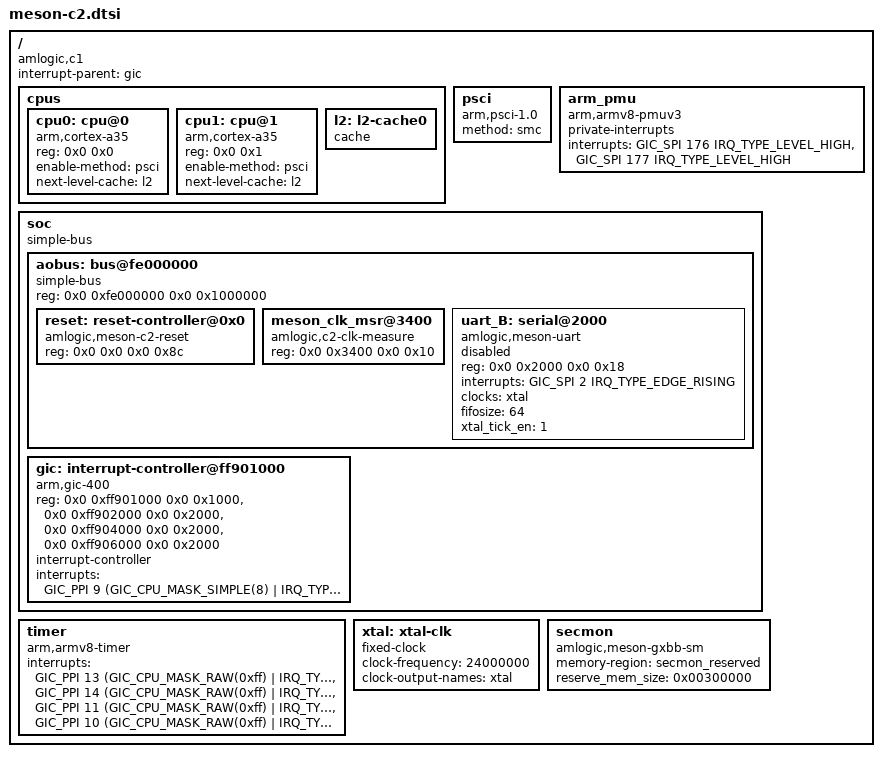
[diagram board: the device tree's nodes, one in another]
// SPDX-License-Identifier: (GPL-2.0+ OR MIT)
/*
 * Copyright (c) 2019 Amlogic, Inc. All rights reserved.
 */

#include <dt-bindings/interrupt-controller/irq.h>
#include <dt-bindings/interrupt-controller/arm-gic.h>

/ {
	compatible = "amlogic,c1";

	interrupt-parent = <&gic>;
	#address-cells = <2>;
	#size-cells = <2>;

	cpus {
		#address-cells = <2>;
		#size-cells = <0>;

		cpu0: cpu@0 {
			device_type = "cpu";
			compatible = "arm,cortex-a35";
			reg = <0x0 0x0>;
			enable-method = "psci";
			next-level-cache = <&l2>;
		};

		cpu1: cpu@1 {
			device_type = "cpu";
			compatible = "arm,cortex-a35";
			reg = <0x0 0x1>;
			enable-method = "psci";
			next-level-cache = <&l2>;
		};

		l2: l2-cache0 {
			compatible = "cache";
		};
	};

	psci {
		compatible = "arm,psci-1.0";
		method = "smc";
	};

	arm_pmu {
		compatible = "arm,armv8-pmuv3";
		/* clusterb-enabled; */
		private-interrupts;
		interrupts = <GIC_SPI 176 IRQ_TYPE_LEVEL_HIGH>,
			     <GIC_SPI 177 IRQ_TYPE_LEVEL_HIGH>;
	};

	soc {
		compatible = "simple-bus";
		#address-cells = <2>;
		#size-cells = <2>;
		ranges;

		aobus: bus@fe000000 {
			compatible = "simple-bus";
			reg = <0x0 0xfe000000 0x0 0x1000000>;
			#address-cells = <2>;
			#size-cells = <2>;
			ranges = <0x0 0x0 0x0 0xfe000000 0x0 0x1000000>;

			reset: reset-controller@0x0 {
				compatible = "amlogic,meson-c2-reset";
				reg = <0x0 0x0 0x0 0x8c>;
				#reset-cells = <1>;
			};

			meson_clk_msr@3400 {
				compatible = "amlogic,c2-clk-measure";
				reg = <0x0 0x3400 0x0 0x10>;
			};

			uart_B: serial@2000 {
				compatible = "amlogic,meson-uart";
				reg = <0x0 0x2000 0x0 0x18>;
				interrupts = <GIC_SPI 2 IRQ_TYPE_EDGE_RISING>;
				status = "disabled";
				clocks = <&xtal>;
				clock-names = "clk_uart";
				fifosize = < 64 >;
				xtal_tick_en = <1>;
				//pinctrl-names = "default";
				//pinctrl-0 = <&b_uart_enable_pins1>;
			};

		};

		gic: interrupt-controller@ff901000 {
			compatible = "arm,gic-400";
			reg = <0x0 0xff901000 0x0 0x1000>,
			      <0x0 0xff902000 0x0 0x2000>,
			      <0x0 0xff904000 0x0 0x2000>,
			      <0x0 0xff906000 0x0 0x2000>;
			interrupt-controller;
			interrupts = <GIC_PPI 9
				(GIC_CPU_MASK_SIMPLE(8) | IRQ_TYPE_LEVEL_HIGH)>;
			#interrupt-cells = <3>;
			#address-cells = <0>;
		};
	};

	timer {
		compatible = "arm,armv8-timer";
		interrupts = <GIC_PPI 13
			(GIC_CPU_MASK_RAW(0xff) | IRQ_TYPE_LEVEL_LOW)>,
			     <GIC_PPI 14
			(GIC_CPU_MASK_RAW(0xff) | IRQ_TYPE_LEVEL_LOW)>,
			     <GIC_PPI 11
			(GIC_CPU_MASK_RAW(0xff) | IRQ_TYPE_LEVEL_LOW)>,
			     <GIC_PPI 10
			(GIC_CPU_MASK_RAW(0xff) | IRQ_TYPE_LEVEL_LOW)>;
	};

	xtal: xtal-clk {
		compatible = "fixed-clock";
		clock-frequency = <24000000>;
		clock-output-names = "xtal";
		#clock-cells = <0>;
	};
	secmon {
		compatible = "amlogic,meson-gxbb-sm";
		memory-region = <&secmon_reserved>;
		reserve_mem_size = <0x00300000>;
	};
};

